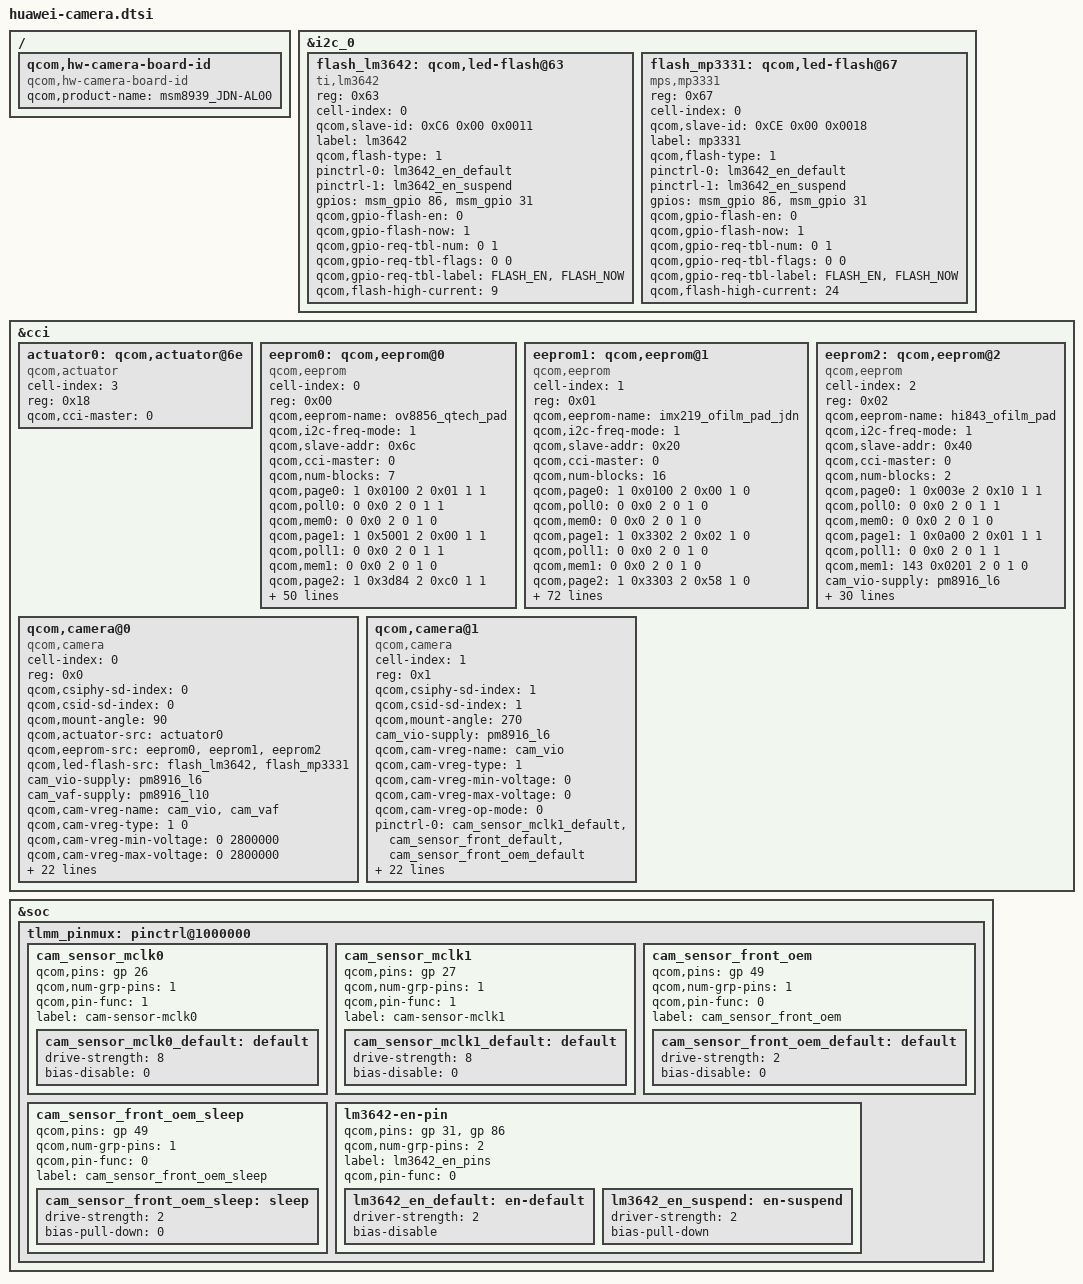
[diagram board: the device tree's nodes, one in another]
/*<CPM2016032300037 yangyale 20160324 begin*/
/*
 * Copyright (c) 2014, The Linux Foundation. All rights reserved.
 *
 * This program is free software; you can redistribute it and/or modify
 * it under the terms of the GNU General Public License version 2 and
 * only version 2 as published by the Free Software Foundation.
 *
 * This program is distributed in the hope that it will be useful,
 * but WITHOUT ANY WARRANTY; without even the implied warranty of
 * MERCHANTABILITY or FITNESS FOR A PARTICULAR PURPOSE.  See the
 * GNU General Public License for more details.
 */     

/ {
    qcom,hw-camera-board-id {
                compatible = "qcom,hw-camera-board-id";
                qcom,product-name = "msm8939_JDN-AL00";
        };
};

&tlmm_pinmux {
	lm3642-en-pin {
		qcom,pins = <&gp 31>, <&gp 86>;
		qcom,num-grp-pins = <2>;
		label = "lm3642_en_pins";
		qcom,pin-func = <0>;

		lm3642_en_default: en-default {
			driver-strength = <2>;
			bias-disable;
		};
		lm3642_en_suspend: en-suspend {
			driver-strength = <2>;
			bias-pull-down;
		};
	};
};

&i2c_0 { /* BLSP1 QUP2 */
	flash_lm3642:qcom,led-flash@63 {
		reg = <0x63>;
		cell-index = <0>;
		qcom,slave-id = <0xC6 0x00 0x0011>;
		compatible = "ti,lm3642";
		label = "lm3642";
		qcom,flash-type = <1>;
		pinctrl-names = "cam_flash_default","cam_flash_suspend";
		pinctrl-0 = <&lm3642_en_default>;
		pinctrl-1 = <&lm3642_en_suspend>;
		gpios = <&msm_gpio 86 0>,
			<&msm_gpio 31 0>;
		qcom,gpio-flash-en = <0>;
		qcom,gpio-flash-now = <1>;
		qcom,gpio-req-tbl-num = <0 1>;
		qcom,gpio-req-tbl-flags = <0 0>;
		qcom,gpio-req-tbl-label = "FLASH_EN",
			"FLASH_NOW";
		qcom,flash-high-current = <9>;/* 937.5mA */
	};
		flash_mp3331:qcom,led-flash@67 {
		reg = <0x67>;
		cell-index = <0>;
		qcom,slave-id = <0xCE 0x00 0x0018>;
		compatible = "mps,mp3331";
		label = "mp3331";
		qcom,flash-type = <1>;
		pinctrl-names = "cam_flash_default","cam_flash_suspend";
		pinctrl-0 = <&lm3642_en_default>;
		pinctrl-1 = <&lm3642_en_suspend>;
		gpios = <&msm_gpio 86 0>,
			<&msm_gpio 31 0>;
		qcom,gpio-flash-en = <0>;
		qcom,gpio-flash-now = <1>;
		qcom,gpio-req-tbl-num = <0 1>;
		qcom,gpio-req-tbl-flags = <0 0>;
		qcom,gpio-req-tbl-label = "FLASH_EN",
			"FLASH_NOW";

		qcom,flash-high-current = <24>;/* 750mA */
	};
};

&cci {
	actuator0: qcom,actuator@6e {
		cell-index = <3>;
		reg = <0x18>;
		compatible = "qcom,actuator";
		qcom,cci-master = <0>;
	};
	eeprom0: qcom,eeprom@0 {
		cell-index = <0>;
		reg = <0x00>;
		qcom,eeprom-name = "ov8856_qtech_pad";
		qcom,i2c-freq-mode = <1> ;
		compatible = "qcom,eeprom";
		qcom,slave-addr = <0x6c>;
		qcom,cci-master = <0>;
		qcom,num-blocks = <7>;
		qcom,page0 = <1 0x0100 2 0x01 1 1>;
		qcom,poll0 = <0 0x0 2 0 1 1>;
		qcom,mem0 = <0 0x0 2 0 1 0>;
		qcom,page1 = <1 0x5001 2 0x00 1 1>;
		qcom,poll1 = <0 0x0 2 0 1 1>;
		qcom,mem1 = <0 0x0 2 0 1 0>;
		qcom,page2 = <1 0x3d84 2 0xc0 1 1>;
		qcom,poll2 = <0 0x0 2 0 1 1>;
		qcom,mem2 = <0 0x0 2 0 1 0>;
		qcom,page3 = <1 0x3d88 2 0x7010 2 1>;
		qcom,poll3 = <0 0x0 2 0 1 1>;
		qcom,mem3 = <0 0x0 2 0 1 0>;
		qcom,page4 = <1 0x3d8a 2 0x720e 2 1>;
		qcom,poll4 = <0 0x0 2 0 1 1>;
		qcom,mem4 = <0 0x0 2 0 1 0>;
		qcom,page5 = <1 0x3d81 2 0x01 1 10>;
		qcom,poll5 = <0 0x0 2 0 1 1>;
		qcom,mem5 = <511 0x7010 2 0 1 1>;
		qcom,page6 = <1 0x5001 2 0x8 1 1>;
		qcom,poll6 = <0 0x0 2 0 1 1>;
		qcom,mem6 = <0 0x0 2 0 1 0>;
		cam_vio-supply = <&pm8916_l6>;
		qcom,cam-vreg-name = "cam_vio";
		qcom,cam-vreg-type = <1>;
		qcom,cam-vreg-min-voltage = <0>;
		qcom,cam-vreg-max-voltage = <0>;
		qcom,cam-vreg-op-mode = <0>;
		pinctrl-names = "cam_default", "cam_suspend";
		pinctrl-0 = <&cam_sensor_mclk0_default &cam_sensor_rear_default>;
		pinctrl-1 = <&cam_sensor_mclk0_sleep &cam_sensor_rear_sleep>;
		gpios = <&msm_gpio 26 0>,
                <&msm_gpio 35 0>,
                <&msm_gpio 34 0>,
                <&msm_gpio 121 0>,//core vreg
                <&msm_gpio 110 0>,
                <&msm_gpio 114 0>;
                qcom,gpio-reset = <1>;
                qcom,gpio-standby = <2>;
                qcom,gpio-vdig = <3>;
                qcom,gpio-vana = <4>;
                qcom,gpio-vio = <5>;
                qcom,gpio-req-tbl-num = <0 1 2 3 4 5>;
                qcom,gpio-req-tbl-flags = <1 0 0 0 0 0>;
                qcom,gpio-req-tbl-label = "CAMIF_MCLK",
                                "CAM_RESET1",
                                "CAM_STANDBY",
                                "CAM_VDIG",
                                "CAM_VANA",
                                "CAM_VIO";
		qcom,cam-power-seq-type = "sensor_gpio",
					  "sensor_gpio",
					  "sensor_gpio",
					  "sensor_gpio",
					  "sensor_gpio",
					  "sensor_gpio",
					  "sensor_gpio",
					  "sensor_clk",
					  "sensor_i2c_mux";
		qcom,cam-power-seq-val = "sensor_gpio_vana",
					  "sensor_gpio_vio",
					  "sensor_gpio_vdig",
					  "sensor_gpio_standby",
					  "sensor_gpio_reset",
					  "sensor_gpio_standby",
					  "sensor_gpio_reset",
					  "sensor_cam_mclk",
					  "none";
		qcom,cam-power-seq-cfg-val = <1 1 1 0 0 1 1 24000000 0>;
		qcom,cam-power-seq-delay = <1 1 1 1 1 5 5 10 0>;
		status = "ok";
		clocks = <&clock_gcc clk_mclk0_clk_src>,
				<&clock_gcc clk_gcc_camss_mclk0_clk>;
		clock-names = "cam_src_clk", "cam_clk";
	};
	eeprom1: qcom,eeprom@1 {
		cell-index = <1>;
		reg = <0x01>;
                qcom,eeprom-name = "imx219_ofilm_pad_jdn";
		qcom,i2c-freq-mode = <1> ;
		compatible = "qcom,eeprom";
		qcom,slave-addr = <0x20>;
		qcom,cci-master = <0>;
		qcom,num-blocks = <16>;
		qcom,page0 = <1 0x0100 2 0x00 1 0>;
		qcom,poll0 = <0 0x0 2 0 1 0>;
		qcom,mem0 = <0 0x0 2 0 1 0>;
		qcom,page1 = <1 0x3302 2 0x02 1 0>;
		qcom,poll1 = <0 0x0 2 0 1 0>;
		qcom,mem1 = <0 0x0 2 0 1 0>;
		qcom,page2 = <1 0x3303 2 0x58 1 0>;
		qcom,poll2 = <0 0x0 2 0 1 0>;
		qcom,mem2 = <0 0x0 2 0 1 0>;
		qcom,page3 = <1 0x012A 2 0x18 1 0>;
		qcom,poll3 = <0 0x0 2 0 1 0>;
		qcom,mem3 = <0 0x0 2 0 1 0>;
		qcom,page4 = <1 0x012B 2 0x00 1 0>;
		qcom,poll4 = <0 0x0 2 0 1 0>;
		qcom,mem4 = <0 0x0 2 0 1 0>;
		qcom,page5 = <1 0x3300 2 0x08 1 0>;
		qcom,poll5 = <0 0x0 2 0 1 0>;
		qcom,mem5 = <0 0x0 2 0 1 0>;
		qcom,page6 = <1 0x3200 2 0x01 1 1>;
		qcom,poll6 = <1 0x3201 2 0x01 1 0>;
		qcom,mem6 = <0 0x0 2 0 1 0>;
		qcom,page7 = <1 0x3202 2 0x00 1 1>;
		qcom,poll7 = <0 0x3201 2 0x01 1 0>;
		qcom,mem7 = <64 0x3204 2 0 1 1>;
		qcom,page8 = <1 0x3202 2 0x01 1 1>;
		qcom,poll8 = <0 0x3201 2 0x01 1 0>;
		qcom,mem8 = <64 0x3204 2 0 1 1>;
		qcom,page9 = <1 0x3202 2 0x02 1 1>;
		qcom,poll9 = <0 0x3201 2 0x01 1 0>;
		qcom,mem9 = <64 0x3204 2 0 1 1>;
		qcom,page10 = <1 0x3202 2 0x03 1 1>;
		qcom,poll10 = <0 0x3201 2 0x01 1 0>;
		qcom,mem10 = <64 0x3204 2 0 1 1>;
		qcom,page11 = <1 0x3202 2 0x04 1 1>;
		qcom,poll11 = <0 0x3201 2 0x01 1 0>;
		qcom,mem11 = <47 0x3204 2 0 1 1>;
		qcom,page12 = <1 0x3202 2 0x07 1 1>;
		qcom,poll12 = <0 0x3201 2 0x01 1 0>;
		qcom,mem12 = <34 0x3222 2 0 1 1>;
		qcom,page13 = <1 0x3202 2 0x08 1 1>;
		qcom,poll13 = <0 0x3201 2 0x01 1 0>;
		qcom,mem13 = <64 0x3204 2 0 1 1>;
		qcom,page14 = <1 0x3202 2 0x09 1 1>;
		qcom,poll14 = <0 0x3201 2 0x01 1 0>;
		qcom,mem14 = <64 0x3204 2 0 1 1>;
		qcom,page15 = <1 0x3202 2 0x0a 1 1>;
		qcom,poll15 = <0 0x3201 2 0x01 1 0>;
		qcom,mem15 = <13 0x3204 2 0 1 1>;
		cam_vio-supply = <&pm8916_l6>;
		qcom,cam-vreg-name = "cam_vio";
		qcom,cam-vreg-type = <1>;
		qcom,cam-vreg-min-voltage = <0>;
		qcom,cam-vreg-max-voltage = <0>;
		qcom,cam-vreg-op-mode = <0>;
		pinctrl-names = "cam_default", "cam_suspend";
		pinctrl-0 = <&cam_sensor_mclk0_default &cam_sensor_rear_default>;
		pinctrl-1 = <&cam_sensor_mclk0_sleep &cam_sensor_rear_sleep>;
		qcom,gpio-no-mux = <0>;
		gpios = <&msm_gpio 26 0>,
                <&msm_gpio 35 0>,
                <&msm_gpio 121 0>,//core vreg
                <&msm_gpio 110 0>,
                <&msm_gpio 114 0>;
                qcom,gpio-reset = <1>;
                qcom,gpio-vdig = <2>;
                qcom,gpio-vana = <3>;
                qcom,gpio-vio = <4>;
                qcom,gpio-req-tbl-num = <0 1 2 3 4>;
                qcom,gpio-req-tbl-flags = <1 0 0 0 0>;
                qcom,gpio-req-tbl-label = "CAMIF_MCLK",
                                "CAM_RESET1",
                                "CAM_VDIG",
                                "CAM_VANA",
                                "CAM_VIO";
		qcom,cam-power-seq-type = "sensor_gpio",
					  "sensor_gpio",
					  "sensor_gpio",
					  "sensor_clk",
					  "sensor_gpio",
					  "sensor_i2c_mux";
		qcom,cam-power-seq-val = "sensor_gpio_vdig",
					  "sensor_gpio_vio",
					  "sensor_gpio_vana",
					  "sensor_cam_mclk",
					  "sensor_gpio_reset",
					  "none";
		qcom,cam-power-seq-cfg-val = <1 1 1 24000000 1 0>;
		qcom,cam-power-seq-delay = <1 1 1 10 1 0>;
		clocks = <&clock_gcc clk_mclk0_clk_src>,
				<&clock_gcc clk_gcc_camss_mclk0_clk>;
		clock-names = "cam_src_clk", "cam_clk";
	};
	/*<CPM2016032300037 wangyi 20160401 begin*/
	eeprom2: qcom,eeprom@2 {
		cell-index = <2>;
		reg = <0x02>;
		qcom,eeprom-name = "hi843_ofilm_pad";
		qcom,i2c-freq-mode = <1> ;
		compatible = "qcom,eeprom";
		qcom,slave-addr = <0x40>;
		qcom,cci-master = <0>;
                qcom,num-blocks = <2>;
                qcom,page0 = <1 0x003e 2 0x10 1 1>;
		qcom,poll0 = <0 0x0 2 0 1 1>;
		qcom,mem0 = <0 0x0 2 0 1 0>;
                qcom,page1 = <1 0x0a00 2 0x01 1 1>;
		qcom,poll1 = <0 0x0 2 0 1 1>;
                qcom,mem1 = <143 0x0201 2 0 1 0>;

		cam_vio-supply = <&pm8916_l6>;
		qcom,cam-vreg-name = "cam_vio";
		qcom,cam-vreg-type = <1>;
		qcom,cam-vreg-min-voltage = <0>;
		qcom,cam-vreg-max-voltage = <0>;
		qcom,cam-vreg-op-mode = <0>;
		pinctrl-names = "cam_default", "cam_suspend";
		pinctrl-0 = <&cam_sensor_mclk0_default &cam_sensor_rear_default>;
		pinctrl-1 = <&cam_sensor_mclk0_sleep &cam_sensor_rear_sleep>;
		qcom,gpio-no-mux = <0>;
		gpios = <&msm_gpio 26 0>,
                <&msm_gpio 35 0>,
                <&msm_gpio 121 0>,//core vreg
                <&msm_gpio 110 0>,
                <&msm_gpio 114 0>;
                qcom,gpio-reset = <1>;
                qcom,gpio-vdig = <2>;
                qcom,gpio-vana = <3>;
                qcom,gpio-vio = <4>;
                qcom,gpio-req-tbl-num = <0 1 2 3 4>;
                qcom,gpio-req-tbl-flags = <1 0 0 0 0>;
                qcom,gpio-req-tbl-label = "CAMIF_MCLK",
                                "CAM_RESET1",
                                "CAM_VDIG",
                                "CAM_VANA",
                                "CAM_VIO";
		qcom,cam-power-seq-type = "sensor_gpio",
					  "sensor_gpio",
					  "sensor_gpio",
                                          "sensor_clk",
					  "sensor_gpio",
					  "sensor_i2c_mux";
                qcom,cam-power-seq-val = "sensor_gpio_vio",
                                         "sensor_gpio_vana",
					  "sensor_gpio_vdig",
                                         "sensor_cam_mclk",
					  "sensor_gpio_reset",
					  "none";
                qcom,cam-power-seq-cfg-val = <1 1 1 24000000 1  0>;
                qcom,cam-power-seq-delay = <1 1 1 10 1 0>;
		clocks = <&clock_gcc clk_mclk0_clk_src>,
				<&clock_gcc clk_gcc_camss_mclk0_clk>;
		clock-names = "cam_src_clk", "cam_clk";
	};

	qcom,camera@0 {
		cell-index = <0>;
		compatible = "qcom,camera";
		reg = <0x0>;
		qcom,csiphy-sd-index = <0>;
		qcom,csid-sd-index = <0>;
		qcom,mount-angle = <90>;
		qcom,actuator-src = <&actuator0>;
		qcom,eeprom-src = <&eeprom0 &eeprom1 &eeprom2>;
                qcom,led-flash-src = <&flash_lm3642 &flash_mp3331>;
		cam_vio-supply = <&pm8916_l6>;
		cam_vaf-supply = <&pm8916_l10>;
		qcom,cam-vreg-name = "cam_vio", "cam_vaf";
		qcom,cam-vreg-type = <1 0>;
		qcom,cam-vreg-min-voltage = <0 2800000>;
		qcom,cam-vreg-max-voltage = <0 2800000>;
		qcom,cam-vreg-op-mode = <0 100000>;
		pinctrl-names = "cam_default", "cam_suspend";
		pinctrl-0 = <&cam_sensor_mclk0_default &cam_sensor_rear_default>;
		pinctrl-1 = <&cam_sensor_mclk0_sleep &cam_sensor_rear_sleep>;
                gpios = <&msm_gpio 26 0>,
                        <&msm_gpio 35 0>,
                        <&msm_gpio 34 0>,
                        <&msm_gpio 121 0>,//core vreg
                        <&msm_gpio 110 0>,
                        <&msm_gpio 114 0>;
                qcom,gpio-reset = <1>;
                qcom,gpio-standby = <2>;
                qcom,gpio-vdig = <3>;
                qcom,gpio-vana = <4>;
                qcom,gpio-vio = <5>;
                qcom,gpio-req-tbl-num = <0 1 2 3 4 5>;
                qcom,gpio-req-tbl-flags = <1 0 0 0 0 0>;
                qcom,gpio-req-tbl-label = "CAMIF_MCLK",
                                "CAM_RESET1",
                                "CAM_STANDBY",
                                "CAM_VDIG",
                                "CAM_VANA",
                                "CAM_VIO";
		qcom,sensor-position = <0>;
		qcom,sensor-mode = <0>;
		qcom,cci-master = <0>;
		status = "ok";
		clocks = <&clock_gcc clk_mclk0_clk_src>,
				<&clock_gcc clk_gcc_camss_mclk0_clk>;
		clock-names = "cam_src_clk", "cam_clk";
	};
	qcom,camera@1 {
		cell-index = <1>;
		compatible = "qcom,camera";
		reg = <0x1>;
		qcom,csiphy-sd-index = <1>;
		qcom,csid-sd-index = <1>;
		qcom,mount-angle = <270>;
		cam_vio-supply = <&pm8916_l6>;
		qcom,cam-vreg-name = "cam_vio";
		qcom,cam-vreg-type = <1>;
		qcom,cam-vreg-min-voltage = <0>;
		qcom,cam-vreg-max-voltage = <0>;
		qcom,cam-vreg-op-mode = <0>;
		pinctrl-names = "cam_default", "cam_suspend";
		pinctrl-0 = <&cam_sensor_mclk1_default &cam_sensor_front_default &cam_sensor_front_oem_default>;
		pinctrl-1 = <&cam_sensor_mclk1_sleep &cam_sensor_front_sleep &cam_sensor_front_oem_sleep>;
		gpios = <&msm_gpio 27 0>,
				<&msm_gpio 28 0>,
				<&msm_gpio 33 0>,
				<&msm_gpio 114 0>,
				<&msm_gpio 110 0>,
				<&msm_gpio 121 0>,//core vreg
				<&msm_gpio 49 0>;
		qcom,gpio-reset = <1>;
		qcom,gpio-standby = <2>;
		qcom,gpio-vio = <3>;
		qcom,gpio-vana = <4>;
		qcom,gpio-vdig = <5>;
		qcom,gpio-cam-id = <6>;
		qcom,gpio-req-tbl-num = <0 1 2 3 4 5 6>;
		qcom,gpio-req-tbl-flags = <1 0 0 0 0 0 1>;
		qcom,gpio-req-tbl-label = "CAMIF_MCLK",
				"CAM_RESET",
				"CAM_STANDBY",
				"CAM_VIO",
				"CAM_VANA",
				"CAM_VDIG",
				"CAM_ID";
		qcom,sensor-position = <1>;
		qcom,sensor-mode = <0>;
		qcom,cci-master = <0>;
		status = "ok";
		clocks = <&clock_gcc clk_mclk1_clk_src>,
				<&clock_gcc clk_gcc_camss_mclk1_clk>;
		clock-names = "cam_src_clk", "cam_clk";
	};
};

&soc {
	tlmm_pinmux: pinctrl@1000000 {
                 cam_sensor_mclk0 {
			/* MCLK */
			qcom,pins = <&gp 26>;
			qcom,num-grp-pins = <1>;
			qcom,pin-func = <1>;
			label = "cam-sensor-mclk0";
			/* active state */
			cam_sensor_mclk0_default: default {
				drive-strength = <8>; /* 8 MA */
				bias-disable = <0>; /* No PULL */
			};
                };
		cam_sensor_mclk1 {
			/* MCLK */
			qcom,pins = <&gp 27>;
			qcom,num-grp-pins = <1>;
			qcom,pin-func = <1>;
			label = "cam-sensor-mclk1";
			/* active state */
			cam_sensor_mclk1_default: default {
				drive-strength = <8>; /* 8 MA */
				bias-disable = <0>; /* No PULL */
			};
                };
		cam_sensor_front_oem {
			/* CAM_GPIO_ID */
			qcom,pins = <&gp 49>;
			qcom,num-grp-pins = <1>;
			qcom,pin-func = <0>;
			label = "cam_sensor_front_oem";
			/* active state */
			cam_sensor_front_oem_default: default {
				drive-strength = <2>; /* 2 MA */
				bias-disable = <0>; /* No PULL */
			};
				};
		cam_sensor_front_oem_sleep {
			/* CAM_GPIO_ID */
			qcom,pins = <&gp 49>;
			qcom,num-grp-pins = <1>;
			qcom,pin-func = <0>;
			label = "cam_sensor_front_oem_sleep";
			/*suspend state */
			cam_sensor_front_oem_sleep: sleep {
				drive-strength = <2>; /* 2 MA */
				bias-pull-down = <0>; /* No PULL */
			};
				};
        };
};
/*CPM2016032300037 yangyale 20160324 end>*/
